# CY8C5868AXI_LP035 register map
File version: 0.1
Registers are 8-bit, read-write, no defined reset value unless marked. A register's access mark holds for its fields unless they carry their own. Offsets are from the block's base; [hi:lo] are bit positions; {n}, {i} and the like mark numbered series; 'fields as' and 'values as' point back to an identical list.

## PGA_1
Base 0x00000000
0x400043A9 SC__PM_ACT_CFG — Active Power Mode Configuration Register 9
  [3:0] en_swcap ro — Enable switchcap block(s)
    1=en_swcap_0_ (Enables SC Block 0); 2=en_swcap_1_ (Enables SC Block 1); 4=en_swcap_2_ (Enables SC Block 2); 8=en_swcap_3_ (Enables SC Block 3)
0x400043B9 SC__PM_STBY_CFG — Standby Power Mode Configuration Register 9
  fields as SC__PM_ACT_CFG
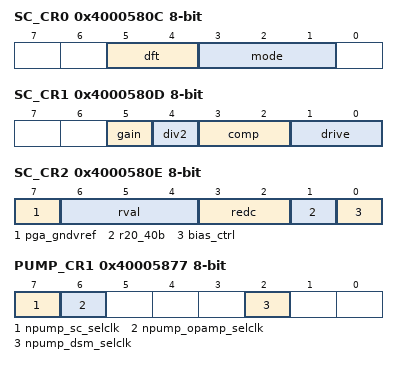
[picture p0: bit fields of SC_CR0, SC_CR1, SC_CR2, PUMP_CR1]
0x4000580C SC_CR0 — Switched Capacitor Control Register 0
  [5:4] dft ro — Configuration select for the SC block
    0=SC_DFT_NORMAL (Normal Operation); 1=SC_DFT_VBOOST (Vboost DFT); 2=SC_DFT_MODE_DEPENDENT (Mode Dependent (PGA Mode = Voltage Integrator, TIA Mode = Charge Integrator, Naked Opamp Mode = Comparator)); 3=SC_DFT_RESET (DFT reset)
  [3:1] mode ro — Configuration select for the SC block
    0=SC_MODE_NAKED_OPAMP (Naked Op-Amp); 1=SC_MODE_TIA (Transimpedance Amplifier); 2=SC_MODE_CTMIXER (Continuous Time Mixer); 3=SC_MODE_NRZ_SH (Discrete Time Mixer - NRZ S/H); 4=SC_MODE_UNITY (Unity Gain Buffer); 5=SC_MODE_1ST_MOD (First Order Modulator); 6=SC_MODE_PGA (Programmable Gain Amplifier (PGA)); 7=SC_MODE_TRACKANDHOLD (Track and Hold)
0x4000580D SC_CR1 — Switched Capacitor Control Register 1
  [5] gain ro — Controls the ratio of the feedback cap for S/H Mixer mode and PGA mode
    0=GAIN_0DB (0 dB); 1=GAIN_6DB (6 dB)
  [4] div2 ro — When 0, the sample clock only needs to be half the desired sample frequency for S/H Mixer mode
    0=SC_DIV2_DISABLEF (no frequency division); 1=SC_DIV2_ENABLE (SC CLK is divided by two)
  [3:2] comp ro — Selects between various compensation capacitor sizes
    0=SC_COMP_3P0PF (3.0pF); 1=SC_COMP_3P6PF (3.6pF); 2=SC_COMP_4P35PF (4.35pF); 3=SC_COMP_5P1PF (5.1pF)
  [1:0] drive ro — Selects between current settings (I_Load (uA)) in the output buffer
    0=I_LOAD_175UA (175 uA); 1=I_LOAD_260UA (260 uA); 2=I_LOAD_330UA (330 uA); 3=I_LOAD_400UA (400 uA)
0x4000580E SC_CR2 — Switched Capacitor Control Register 2
  [7] pga_gndvref ro — Programmable Gain Amplifier Application - Ground VREF)
    0=SC_PGA_GNDVREF_DIS (VREF not grounded); 1=SC_PGA_GNDVREF_EN (VREF grounded)
  [6:4] rval — Programmable Gain Amplifier (PGA) and Transimpedance Amplifier (TIA): Feedback resistor (Rfb)
    0=SC_RVAL_20 (20 kOhm); 1=SC_RVAL_30 (30 kOhm); 2=SC_RVAL_40 (40 kOhm); 3=SC_RVAL_80 (80 kOhm); 4=SC_RVAL_120 (120 kOhm); 5=SC_RVAL_250 (250 kOhm); 6=SC_RVAL_500 (500 kOhm); 7=SC_RVAL_1000 (1 MegaOhm)
  [3:2] redc — Another stability control setting. Adjusts capactiance between amplifier output and first stage
    0=SC_REDC_00 (Varies depending on mode. See Switched Cap documentation); 1=SC_REDC_01 (Varies depending on mode. See Switched Cap documentation); 2=SC_REDC_10 (Varies depending on mode. See Switched Cap documentation); 3=SC_REDC_11 (Varies depending on mode. See Switched Cap documentation)
  [1] r20_40b — PGA Mode: input impedance (Rin), Mixer Mode: input and feedback impedance (Rmix)
    0=SC_R20_40B_40K (40kOhm); 1=SC_R20_40B_20K (20kOhm)
  [0] bias_ctrl ro — Toggles the bias current in the amplifier between normal and 1/2
    0=BIAS_1X (1x current reference reduces bandwidth to increase stability); 1=BIAS_2X (normal operation - 2x current reference to increase bandwidth)
0x40005877 PUMP_CR1 — Pump Configuration Register 1
  [7] npump_sc_selclk ro — Switched Cap Negative Pump Clock Selection
    0=NPUMP_SC_SELCLK_EXTERNAL (External (DSI) clock selected); 1=NPUMP_SC_SELCLK_INTERNAL_ (Negative pump internal clock selected)
  [6] npump_opamp_selclk ro — Opamp Negative Pump Clock Selection
    0=NPUMP_OPAMP_SELCLK_EXTERNAL (External (DSI) clock selected); 1=NPUMP_OPAMP_SELCLK_INTERNAL_ (Negative pump internal clock selected)
  [2] npump_dsm_selclk ro — DSM Negative Pump Clock Selection
    0=NPUMP_DSM_SELCLK_EXTERNAL (External (DSI) clock selected); 1=NPUMP_DSM_SELCLK_INTERNAL (Negative pump internal clock selectedd)
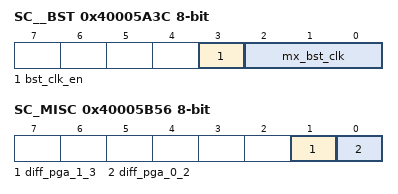
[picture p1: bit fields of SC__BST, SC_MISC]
0x40005A3C SC__BST — Switched Capacitor Boost Clock Selection Register
  [3] bst_clk_en — Clock gating control
    0=CLK_EN_0 (disable clock); 1=CLK_EN_1 (enable clock)
  [2:0] mx_bst_clk — Clock Selection
    {v}=MX_CLK_{v} (Select clk_a{v} and clk_a{v}_dig) (v=0..3); 4=MX_CLK_4 (Select UDB generated clock); 5=MX_CLK_5 (Reserved); 6=MX_CLK_6 (Reserved); 7=MX_CLK_7 (Reserved)
0x40005B56 SC_MISC — Switched Cap Miscellaneous Control Register
  [1] diff_pga_1_3 ro — Switched Cap Pair Connect for Differential Amplifier Applications
    0=SC_DIFF_PGA_DISABLED (Differential PGA pair connect disabled); 1=SC_DIFF_PGA_ENABLED (Differential PGA pair connect enabled)
  [0] diff_pga_0_2 ro — Switched Cap Pair Connect for Differential Amplifier Applications
    0=SC_DIFF_PGA_DISABLED (Differential PGA pair connect disabled); 1=SC_DIFF_PGA_ENABLED_ (Differential PGA pair connect enabled)

## VDAC8_1
Base 0x00000000
0x400043A8 VDAC8_PM_ACT_CFG — Active Power Mode Configuration Register 8
  [4:0] en_dac — Enable DAC block(s). Populated subsystems are counted from the LSB
0x400043B8 VDAC8_PM_STBY_CFG — Standby Power Mode Configuration Register 8
  fields as VDAC8_PM_ACT_CFG
0x4000460B VDAC8_TR
  [7:0] tr — 8 Calibration bits
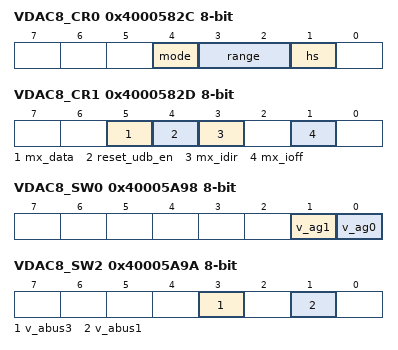
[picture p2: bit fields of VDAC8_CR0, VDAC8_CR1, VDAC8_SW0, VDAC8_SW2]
0x4000582C VDAC8_CR0 — DAC Block Control Register 0
  [4] mode ro — Mode Bit
    0=DAC_MODE_V (voltage DAC); 1=DAC_MODE_I (current DAC)
  [3:2] range — Ranges for mode=0 (VDAC) and mode=1 (IDAC)
    0=DAC_RANGE_0 (x0=0V to 4*vref (1.024V); 0 to 31.875uA); 1=DAC_RANGE_1 (x1=0V to 16*vref (4.096V); 0 to 255uA); 2=DAC_RANGE_2 (x0=0V to 4*vref (1.024V); 0 to 2.040mA); 3=DAC_RANGE_3 (x1=0V to 16*vref (4.096V); not used)
  [1] hs — High Speed Bit
    0=DAC_HS_LOWPOWER (regular (low power)); 1=DAC_HS_HIGHSPEED (high speed (higher power))
0x4000582D VDAC8_CR1 — DAC Block Control Register 1
  [5] mx_data — Select DATA source
    0=MX_DATA_REG (Select register source (DACxn_D)); 1=MX_DATA_UDB (Select UDB source)
  [4] reset_udb_en — DAC reset enable
    0=RESET_UDB_EN_DISABLE (Disable DAC Reset Source from UDB (System reset always resets)); 1=RESET_UDB_EN_ENABLE (Enable DAC Reset Source from UDB)
  [3] mx_idir — Mux selection for DAC current direction control
    0=MX_IDIR_REG (Register source idirbit selected); 1=MX_IDIR_UDB (UDB ictrl selected)
  [1] mx_ioff — Mux selection for DAC current off control
    0=MX_IOFF_REG (Register source ioffbit selected); 1=MX_IOFF_UDB (UDB ictrl selected)
0x40005A98 VDAC8_SW0 — DAC Analog Routing Register 0
  [1] v_ag1 — Connect voltage output to analog global of same side
    0=AG_NC (not connected); 1=AG_CONNECTED (Connect to Analog Global)
  [0] v_ag0 — Connect voltage output to analog global of same side
    values as v_ag1
0x40005A9A VDAC8_SW2 — DAC Analog Routing Register 2
  [3] v_abus3 — Connect voltage output to analog (local) bus of the same side
    0=ABUS_NC (not connected); 1=ABUS_CONNECTED (Connect to Analog (local) Bus)
  [1] v_abus1 — Connect voltage output to analog (local) bus of the same side
    values as v_abus3
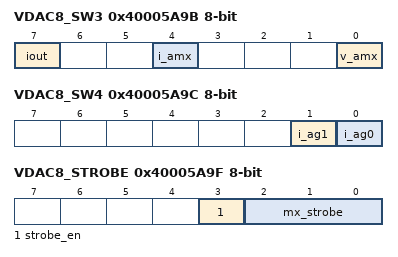
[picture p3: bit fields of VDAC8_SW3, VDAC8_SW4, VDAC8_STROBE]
0x40005A9B VDAC8_SW3 — DAC Analog Routing Register 3
  [7] iout — Connect current output to pad
    0=IOUT_NC (not connected); 1=IOUT_CONNECT (Connect to pad)
  [4] i_amx — Connect current output to Analog Mux Bus
    0=AMX_NC (not connected); 1=AMX_CONNECTED (Connect to AMUXBUS)
  [0] v_amx — Connect voltage output to Analog Mux Bus
    values as i_amx
0x40005A9C VDAC8_SW4 — DAC Analog Routing Register 4
  [1] i_ag1 — Connect current output to analog global of same side
    values as VDAC8_SW0.v_ag1
  [0] i_ag0 — Connect current output to analog global of same side
    values as VDAC8_SW0.v_ag1
0x40005A9F VDAC8_STROBE — DAC Strobe Register
  [3] strobe_en — Strobe gating control (See mx_strobe==3'h0)
    0=disable strobe; 1=enable strobe
  [2:0] mx_strobe — Strobe source selection
    0=MX_STROBE_BUSWRITE (Select bus write strobe source (Enable gater regardless of strobe_en setting)); 1=MX_STROBE_UDB_SRC (Select UDB strobe source); 2=MX_STROBE_NC_2 (NC); 3=MX_STROBE_NC_3 (NC); {v}=MX_STROBE_CLK_A{v-4}_DIG (Select clk_a{v-4}_dig) (v=4..7)
0x40005B83 VDAC8_DATA — DAC Data Register
  [7:0] data — 8 DAC Data bits

## UART_1 — UART
Base 0x00000000
0x40006448 TX_UART_1_TX_DATA — TX Data Register
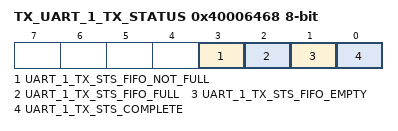
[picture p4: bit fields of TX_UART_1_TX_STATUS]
0x40006468 TX_UART_1_TX_STATUS — TX status register
  [3] UART_1_TX_STS_FIFO_NOT_FULL ro, [2] UART_1_TX_STS_FIFO_FULL ro, [1] UART_1_TX_STS_FIFO_EMPTY ro, [0] UART_1_TX_STS_COMPLETE ro
